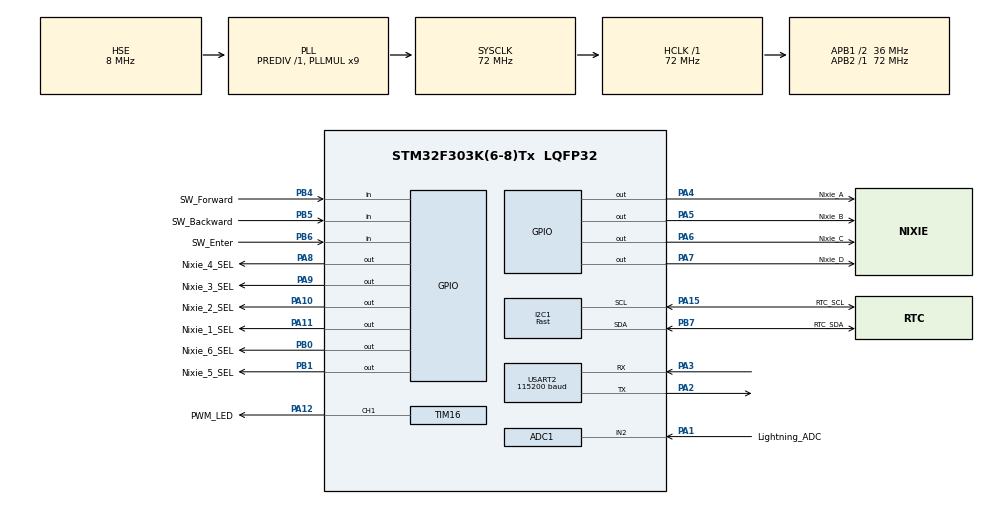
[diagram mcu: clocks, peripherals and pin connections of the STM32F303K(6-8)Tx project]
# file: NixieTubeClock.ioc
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Mcu.Family=STM32F3
NVIC.ADC1_2_IRQn=true\:0\:0\:false\:false\:true\:true\:true
TIM17.Prescaler=72-1
RCC.CortexFreq_Value=72000000
VP_TIM17_VS_ClockSourceINT.Mode=Enable_Timer
Dma.ADC1.1.MemDataAlignment=DMA_MDATAALIGN_HALFWORD
I2C1.I2C_Speed_Mode=I2C_Fast
PF0\ /\ OSC_IN.Mode=HSE-External-Oscillator
I2C1.I2C_Rise_Time=300
RCC.SYSCLKSourceVirtual=RCC_SYSCLKSOURCE_PLLCLK
PB7.GPIO_FM7=__NULL
PA7.GPIO_ModeDefaultOutputPP=GPIO_MODE_OUTPUT_PP
PB6.GPIO_Label=SW_Enter
PB0.GPIO_Label=Nixie_6_SEL
PA6.GPIO_Label=Nixie_C
ProjectManager.StackSize=0x400
PA15.GPIO_Label=RTC_SCL
PA12.Signal=S_TIM16_CH1
Dma.USART2_RX.0.Priority=DMA_PRIORITY_LOW
Dma.ADC1.1.Instance=DMA1_Channel1
ADC1.Offset-0\#ChannelRegularConversion=0
Dma.USART2_RX.0.PeriphDataAlignment=DMA_PDATAALIGN_BYTE
RCC.HCLKFreq_Value=72000000
RCC.APB2TimFreq_Value=72000000
PB6.Signal=GPIO_Input
Dma.ADC1.1.PeriphDataAlignment=DMA_PDATAALIGN_HALFWORD
ADC1.SubFamily=STM32F303x8
RCC.AHBFreq_Value=72000000
ADC1.Channel-0\#ChannelRegularConversion=ADC_CHANNEL_2
RCC.HSE_VALUE=8000000
USART2.VirtualMode-Asynchronous=VM_ASYNC
PA15.Mode=I2C
RCC.PLLMUL=RCC_PLL_MUL9
TIM17.Period=1
NVIC.TIM1_TRG_COM_TIM17_IRQn=true\:0\:0\:false\:false\:true\:true\:true
Dma.USART2_RX.0.MemDataAlignment=DMA_MDATAALIGN_BYTE
PA14.Mode=Serial_Wire
PB1.GPIO_Label=Nixie_5_SEL
PA10.GPIO_Label=Nixie_2_SEL
Dma.USART2_RX.0.Instance=DMA1_Channel6
Dma.ADC1.1.Priority=DMA_PRIORITY_LOW
PB7.Signal=I2C1_SDA
Dma.ADC1.1.Mode=DMA_NORMAL
PA8.Signal=GPIO_Output
ADC1.SamplingTime-0\#ChannelRegularConversion=ADC_SAMPLETIME_1CYCLE_5
PB7.GPIO_Label=RTC_SDA
Mcu.Package=LQFP32
PB1.Signal=GPIO_Output
PA6.Signal=GPIO_Output
Dma.USART2_RX.0.PeriphInc=DMA_PINC_DISABLE
Dma.ADC1.1.Direction=DMA_PERIPH_TO_MEMORY
Dma.ADC1.1.MemInc=DMA_MINC_ENABLE
PA10.Signal=GPIO_Output
PA15.Signal=I2C1_SCL
PA4.GPIO_ModeDefaultOutputPP=GPIO_MODE_OUTPUT_PP
PA6.GPIO_ModeDefaultOutputPP=GPIO_MODE_OUTPUT_PP
PB5.GPIO_Label=SW_Backward
Dma.Request1=ADC1
RCC.APB1TimFreq_Value=72000000
TIM16.Prescaler=72-1
Dma.Request0=USART2_RX
PA4.GPIO_Label=Nixie_A
PB4.Signal=GPIO_Input
PA3.Signal=USART2_RX
RCC.PLLSourceVirtual=RCC_PLLSOURCE_HSE
NVIC.DMA1_Channel6_IRQn=true\:0\:0\:false\:false\:true\:false\:true
ADC1.Rank-0\#ChannelRegularConversion=1
I2C1.I2C_Fall_Time=300
ADC1.OffsetNumber-0\#ChannelRegularConversion=ADC_OFFSET_NONE
PA9.GPIO_Label=Nixie_3_SEL
PB6.GPIO_PuPd=GPIO_PULLUP
Dma.USART2_RX.0.Direction=DMA_PERIPH_TO_MEMORY
PA11.GPIO_Label=Nixie_1_SEL
SH.S_TIM16_CH1.0=TIM16_CH1,PWM Generation1 CH1
VP_TIM16_VS_ClockSourceINT.Mode=Enable_Timer
RCC.APB1CLKDivider=RCC_HCLK_DIV2
NVIC.USART2_IRQn=true\:0\:0\:false\:false\:true\:true\:true
TIM16.Channel=TIM_CHANNEL_1
USART2.BaudRate=115200
PA12.GPIO_Label=PWM_LED
Dma.USART2_RX.0.Mode=DMA_CIRCULAR
PA13.Signal=SYS_JTMS-SWDIO
PA3.Mode=Asynchronous
PA8.GPIO_Label=Nixie_4_SEL
ProjectManager.TargetToolchain=STM32CubeIDE
PA9.Signal=GPIO_Output
I2C1.Timing=0x00300208
PB4.GPIO_PuPd=GPIO_PULLUP
PF1\ /\ OSC_OUT.Signal=RCC_OSC_OUT
PA1.Signal=ADC1_IN2
PA5.Signal=GPIO_Output
board=custom
TIM16.Period=100
RCC.APB2Freq_Value=72000000
PA1.Mode=IN2-Single-Ended
PF0\ /\ OSC_IN.Signal=RCC_OSC_IN
PB4.GPIO_Label=SW_Forward
PA5.GPIO_ModeDefaultOutputPP=GPIO_MODE_OUTPUT_PP
VP_TIM2_VS_ClockSourceINT.Mode=Internal
PA1.GPIO_Label=Lightning_ADC
Dma.ADC1.1.PeriphInc=DMA_PINC_DISABLE
PB7.GPIO_PuPdOD=GPIO_NOPULL
PA13.Mode=Serial_Wire
Mcu.Name=STM32F303K(6-8)Tx
Dma.USART2_RX.0.MemInc=DMA_MINC_ENABLE
PA2.Signal=USART2_TX
PA4.Signal=GPIO_Output
RCC.SYSCLKFreq_VALUE=72000000
PB5.Signal=GPIO_Input
PA7.GPIO_Label=Nixie_D
ADC1.master=1
PA5.GPIO_Label=Nixie_B
PB5.GPIO_PuPd=GPIO_PULLUP
PB7.Mode=I2C
PA11.Signal=GPIO_Output
PA14.Signal=SYS_JTCK-SWCLK
ProjectManager.HeapSize=0x200
PA15.GPIO_PuPdOD=GPIO_NOPULL
RCC.HSI_VALUE=8000000
NVIC.PriorityGroup=NVIC_PRIORITYGROUP_4
ADC1.NbrOfConversionFlag=1
PA2.Mode=Asynchronous
NVIC.DMA1_Channel1_IRQn=true\:0\:0\:false\:false\:true\:false\:true
RCC.APB1Freq_Value=36000000
PB0.Signal=GPIO_Output
PF1\ /\ OSC_OUT.Mode=HSE-External-Oscillator
PA7.Signal=GPIO_Output

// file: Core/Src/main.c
/* USER CODE BEGIN Header */
/**
  ******************************************************************************
  * @file           : main.c
  * @brief          : Main program body
  ******************************************************************************
  * @attention
  *
  * <h2><center>&copy; Copyright (c) 2020 STMicroelectronics.
  * All rights reserved.</center></h2>
  *
  * This software component is licensed by ST under BSD 3-Clause license,
  * the "License"; You may not use this file except in compliance with the
  * License. You may obtain a copy of the License at:
  *                        opensource.org/licenses/BSD-3-Clause
  *
  ******************************************************************************
  */
/* USER CODE END Header */
#include "main.h"
#include "adc.h"
#include "dma.h"
#include "i2c.h"
#include "tim.h"
#include "usart.h"
#include "gpio.h"

/* USER CODE BEGIN Includes */
#include "nixie_main.h"

/* USER CODE END Includes */

void SystemClock_Config(void);

int main(void)
{

  /* MCU Configuration--------------------------------------------------------*/

  /* Reset of all peripherals, Initializes the Flash interface and the Systick. */
  HAL_Init();

  /* Configure the system clock */
  SystemClock_Config();

  /* Initialize all configured peripherals */
  MX_GPIO_Init();
  MX_DMA_Init();
  MX_I2C1_Init();
  MX_USART2_UART_Init();
  MX_ADC1_Init();
  MX_TIM2_Init();
  MX_TIM16_Init();
  MX_TIM17_Init();
  /* USER CODE BEGIN 2 */
  nixie_main_init();
  /* USER CODE END 2 */

  /* Infinite loop */
  while (1)
  {

    /* USER CODE BEGIN 3 */
    nixie_main();
  }
  /* USER CODE END 3 */
}

void SystemClock_Config(void)
{
  RCC_OscInitTypeDef RCC_OscInitStruct = {0};
  RCC_ClkInitTypeDef RCC_ClkInitStruct = {0};
  RCC_PeriphCLKInitTypeDef PeriphClkInit = {0};

  /** Initializes the RCC Oscillators according to the specified parameters
  * in the RCC_OscInitTypeDef structure.
  */
  RCC_OscInitStruct.OscillatorType = RCC_OSCILLATORTYPE_HSI|RCC_OSCILLATORTYPE_HSE;
  RCC_OscInitStruct.HSEState = RCC_HSE_ON;
  RCC_OscInitStruct.HSEPredivValue = RCC_HSE_PREDIV_DIV1;
  RCC_OscInitStruct.HSIState = RCC_HSI_ON;
  RCC_OscInitStruct.HSICalibrationValue = RCC_HSICALIBRATION_DEFAULT;
  RCC_OscInitStruct.PLL.PLLState = RCC_PLL_ON;
  RCC_OscInitStruct.PLL.PLLSource = RCC_PLLSOURCE_HSE;
  RCC_OscInitStruct.PLL.PLLMUL = RCC_PLL_MUL9;
  if (HAL_RCC_OscConfig(&RCC_OscInitStruct) != HAL_OK)
  {
    Error_Handler();
  }
  /** Initializes the CPU, AHB and APB buses clocks
  */
  RCC_ClkInitStruct.ClockType = RCC_CLOCKTYPE_HCLK|RCC_CLOCKTYPE_SYSCLK
                              |RCC_CLOCKTYPE_PCLK1|RCC_CLOCKTYPE_PCLK2;
  RCC_ClkInitStruct.SYSCLKSource = RCC_SYSCLKSOURCE_PLLCLK;
  RCC_ClkInitStruct.AHBCLKDivider = RCC_SYSCLK_DIV1;
  RCC_ClkInitStruct.APB1CLKDivider = RCC_HCLK_DIV2;
  RCC_ClkInitStruct.APB2CLKDivider = RCC_HCLK_DIV1;

  if (HAL_RCC_ClockConfig(&RCC_ClkInitStruct, FLASH_LATENCY_2) != HAL_OK)
  {
    Error_Handler();
  }
  PeriphClkInit.PeriphClockSelection = RCC_PERIPHCLK_I2C1|RCC_PERIPHCLK_ADC12;
  PeriphClkInit.Adc12ClockSelection = RCC_ADC12PLLCLK_DIV1;
  PeriphClkInit.I2c1ClockSelection = RCC_I2C1CLKSOURCE_HSI;
  if (HAL_RCCEx_PeriphCLKConfig(&PeriphClkInit) != HAL_OK)
  {
    Error_Handler();
  }
}

void Error_Handler(void)
{
}

/************************ (C) COPYRIGHT STMicroelectronics *****END OF FILE****/
